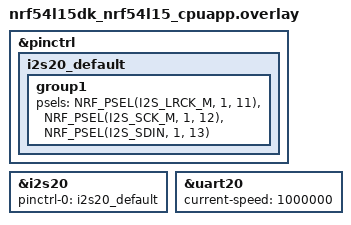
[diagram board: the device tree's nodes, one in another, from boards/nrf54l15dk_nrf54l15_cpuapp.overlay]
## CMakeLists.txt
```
#
# Copyright (c) 2024 Nordic Semiconductor
#
# SPDX-License-Identifier: LicenseRef-Nordic-5-Clause
#

cmake_minimum_required(VERSION 3.20.0)
find_package(Zephyr REQUIRED HINTS $ENV{ZEPHYR_BASE})
project(conn_time_sync)

target_include_directories(app PRIVATE include)
target_sources(app PRIVATE src/main.c src/timed_led_toggle.c src/timed_i2s.c src/buttons_leds.c)

if (CONFIG_BT_CENTRAL)
    target_sources(app PRIVATE src/central.c)
endif()

if (CONFIG_BT_PERIPHERAL)
    target_sources(app PRIVATE src/peripheral.c)
endif()

if (CONFIG_SOC_SERIES_NRF54LX)
    target_sources(app PRIVATE src/controller_time_nrf54.c)
else()
    MESSAGE(FATAL_ERROR "Unsupported series")
endif()
```

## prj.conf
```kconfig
#
# Copyright (c) 2024 Nordic Semiconductor
#
# SPDX-License-Identifier: LicenseRef-Nordic-5-Clause
#

CONFIG_NCS_SAMPLES_DEFAULTS=y

CONFIG_BT_DEVICE_NAME="Conn time sync"
CONFIG_BT=y
CONFIG_BT_PERIPHERAL=y
CONFIG_BT_CENTRAL=y
CONFIG_BT_MAX_CONN=3
CONFIG_BT_CTLR_SDC_PERIPHERAL_COUNT=1

CONFIG_BT_GATT_CLIENT=y

CONFIG_CONSOLE=y
CONFIG_CONSOLE_SUBSYS=y
CONFIG_CONSOLE_HANDLER=y
CONFIG_CONSOLE_GETCHAR=y

CONFIG_BT_CTLR_SDC_CONN_ANCHOR_POINT_REPORT=y
CONFIG_BT_HCI_VS_EVT_USER=y

CONFIG_NRFX_GPPI=y

CONFIG_I2S=y

CONFIG_FLASH=y
CONFIG_FLASH_MAP=y

CONFIG_SPI=y
CONFIG_SPI_NOR=y
CONFIG_SPI_NOR_FLASH_LAYOUT_PAGE_SIZE=4096
CONFIG_NORDIC_QSPI_NOR=n 
```

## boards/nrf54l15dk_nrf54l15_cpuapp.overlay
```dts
&pinctrl {
	i2s20_default: i2s20_default {
		group1 {
			psels = <NRF_PSEL(I2S_LRCK_M, 1, 11)>,
				<NRF_PSEL(I2S_SCK_M, 1, 12)>,
				<NRF_PSEL(I2S_SDIN, 1, 13)>;
		};
	};
};

&i2s20 {
	status = "okay";
	pinctrl-0 = <&i2s20_default>;
	pinctrl-names = "default";
};

&uart20 {
	current-speed = <1000000>;
};
```

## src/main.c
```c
/*
 * Copyright (c) 2024 Nordic Semiconductor ASA
 *
 * SPDX-License-Identifier: LicenseRef-Nordic-5-Clause
 */

#include "conn_time_sync.h"

int main(void)
{
	choose_device_role();
}
```

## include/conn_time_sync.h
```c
/*
 * Copyright (c) 2024 Nordic Semiconductor ASA
 *
 * SPDX-License-Identifier: LicenseRef-Nordic-5-Clause
 */

#ifndef CONN_TIME_SYNC_H__
#define CONN_TIME_SYNC_H__

/**
 * @file
 * @defgroup conn_time_sync Definitions for the connection time sync application.
 * @{
 * @brief Definitions for the connection time sync application.
 *
 * This file contains common definitions and API declarations
 * used by the application.
 */

#include <stdint.h>
#include <stdbool.h>
#include <zephyr/kernel.h>

/** @brief  Timed action service UUID */
#define BT_UUID_TIMED_ACTION_SERVICE_VAL \
	BT_UUID_128_ENCODE(0xA88278D0, 0x7009, 0x4BEE, 0xA6F8, 0xE1DC3FF02B92)
#define BT_UUID_TIMED_ACTION_SERVICE \
	BT_UUID_DECLARE_128(BT_UUID_TIMED_ACTION_SERVICE_VAL)

/** @brief Timed action characteristic UUID */
#define BT_UUID_TIMED_ACTION_CHAR_VAL \
	BT_UUID_128_ENCODE(0xA88278D1, 0x7009, 0x4BEE, 0xA6F8, 0xE1DC3FF02B92)
#define BT_UUID_TIMED_ACTION_CHAR \
	BT_UUID_DECLARE_128(BT_UUID_TIMED_ACTION_CHAR_VAL)

/** @brief Start central demo. */
void central_start(void);

/** @brief Start peripheral demo. */
void peripheral_start(void);

/** @brief The timed action message
 *
 * The timed action message represents the information
 * sent from the central to the peripheral to allow time synchronization.
 * The anchor point information is the common time reference between
 * the central and peripheral.
 *
 * This samples transmits the anchor point time and trigger time
 * in a single packet. Other applications may consider sending those
 * separately.
 */
struct timed_action {
	uint64_t anchor_point_us_central_clock;
	uint16_t anchor_point_event_counter;
	uint64_t trigger_time_us_central_clock;
	bool led_value;
} __packed;

static inline void timed_action_print(struct timed_action *action)
{
	printk("c_anchor point (time=%llu, counter=%u), c_trigger_time %llu, value %d\n",
		action->anchor_point_us_central_clock,
		action->anchor_point_event_counter,
		action->trigger_time_us_central_clock,
		action->led_value);
}

/** @brief Obtain the current Bluetooth controller time.
 *
 * The timestamps are based upon this clock.
 *
 * @return The current controller time.
 */
uint64_t controller_time_us_get(void);

/** @brief Set the controller to trigger a PPI event at the given timestamp.
 *
 * @param timestamp_us The timestamp where it will trigger.
 */
void controller_time_trigger_set(uint64_t timestamp_us);

/** @brief Get the address of the event that will trigger.
 *
 * @return The address of the event that will trigger.
 */
uint32_t controller_time_trigger_event_addr_get(void);

/** @brief Initialize the module handling timed toggling of an LED.
 *
 * @return 0 on success, failure otherwise.
 */
int timed_led_toggle_init(void);

/** @brief Toggle the LED using the given value at the given timestamp.
 *
 * @param value The LED value.
 * @param timestamp_us The time when the LED will be set, in microseconds.
 *                     The time is specified in controller clock units.
 */
void timed_led_toggle_trigger_at(uint8_t value, uint32_t timestamp_us);

/** @brief Initialize the flash for storing timed I2S data by erasing.
 *
 * @return 0 on success, failure otherwise.
 */
int timed_i2s_flash_init(void);

/** @brief Dump flash over UART in chunks.
 * 
 */
void timed_i2s_flash_dump(void);

/** @brief Initialize the module handling timed I2S and set up a PPI channel to capture the local clock.
 *
 * @return 0 on success, failure otherwise.
 */
int timed_i2s_init(void);

/** @brief Read I2S values and write the timestamped data to flash.
 *
 * @return 0 on success, failure otherwise.
 */
int timed_i2s_read(void);

/** @brief Stop the I2S stream and clear the queue.
 *
 * @return 0 on success, failure otherwise.
 */
int timed_i2s_drop(void);

/** @brief Update the time difference between the central and local clock.
 *
 * @param time_diff_us The new time difference.
 */
void timed_i2s_set_time_diff(uint64_t time_diff_us);

/** @brief Choose the device role with buttons.
 *
 * @return 0 on success, failure otherwise.
 */
int choose_device_role(void);

/** @brief Turn the given LED on.
 *
 * @param led The LED number.
 */
void led_on(int led);

/** @brief Wait for a button press while debouncing the input.
 * 
 */
void wait_for_button_press(void);

#endif

/**
 * @}
 */
```

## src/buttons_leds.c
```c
#include <zephyr/drivers/gpio.h>
#include "conn_time_sync.h"

#define SW1_NODE DT_ALIAS(sw1)
#define SW2_NODE DT_ALIAS(sw2)
#define SW3_NODE DT_ALIAS(sw3)

#define LED0_NODE DT_ALIAS(led0)
#define LED2_NODE DT_ALIAS(led2)
#define LED3_NODE DT_ALIAS(led3)

static const struct gpio_dt_spec button1 = GPIO_DT_SPEC_GET(SW1_NODE, gpios);
static const struct gpio_dt_spec button2 = GPIO_DT_SPEC_GET(SW2_NODE, gpios);
static const struct gpio_dt_spec button3 = GPIO_DT_SPEC_GET(SW3_NODE, gpios);

static const struct gpio_dt_spec led0 = GPIO_DT_SPEC_GET(LED0_NODE, gpios);
static const struct gpio_dt_spec led2 = GPIO_DT_SPEC_GET(LED2_NODE, gpios);
static const struct gpio_dt_spec led3 = GPIO_DT_SPEC_GET(LED3_NODE, gpios);

int choose_device_role(void)
{
    if (!device_is_ready(button1.port) || !device_is_ready(button2.port) || !device_is_ready(button3.port)) {
        printk("Button devices are not ready\n");
        return -1;
    }

    if (!device_is_ready(led0.port) || !device_is_ready(led2.port) || !device_is_ready(led3.port)) {
        printk("LED devices are not ready\n");
        return -1;
    }

	gpio_pin_configure_dt(&button1, GPIO_INPUT);
    gpio_pin_configure_dt(&button2, GPIO_INPUT);
    gpio_pin_configure_dt(&button3, GPIO_INPUT);

    gpio_pin_configure_dt(&led0, GPIO_OUTPUT_INACTIVE);
    gpio_pin_configure_dt(&led2, GPIO_OUTPUT_INACTIVE);
    gpio_pin_configure_dt(&led3, GPIO_OUTPUT_INACTIVE);

    printk("Press Button 1 to dump flash data, Button 2 for CENTRAL role, or Button 3 for PERIPHERAL role.\n");

	while (1) {
        if (gpio_pin_get_dt(&button1) == 1) {
        	k_msleep(250);
            timed_i2s_flash_dump();
            led_on(3);
            break;
        }

        if (gpio_pin_get_dt(&button2) == 1) {
        	k_msleep(250);
            printk("Central. Starting scanning\n");
            central_start();
            break;
        }

        if (gpio_pin_get_dt(&button3) == 1) {
        	k_msleep(250);
            printk("Peripheral. Starting advertising\n");
            peripheral_start();
            break;
        }

        k_msleep(50);
    }

    return 0;
}

void led_on(int led)
{
    if (led == 0) {
        gpio_pin_set_dt(&led0, 1);
    } else if (led == 2) {
        gpio_pin_set_dt(&led2, 1);
    } else if (led == 3) {
        gpio_pin_set_dt(&led3, 1);
    }
}

void wait_for_button_press(void)
{
    while (1) {
        if (gpio_pin_get_dt(&button1) == 1) {
        	k_msleep(250);
            break;
        }
        k_msleep(50);
    }
}
```

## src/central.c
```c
/*
 * Copyright (c) 2024 Nordic Semiconductor ASA
 *
 * SPDX-License-Identifier: LicenseRef-Nordic-5-Clause
 */

#include <zephyr/sys/atomic.h>
#include <zephyr/bluetooth/bluetooth.h>
#include <zephyr/bluetooth/conn.h>
#include <zephyr/bluetooth/hci.h>
#include <bluetooth/services/nus.h>
#include "conn_time_sync.h"
#include <bluetooth/hci_vs_sdc.h>

#define LED_TOGGLE_TIME_OFFSET_US 50000

#define ADV_NAME_STR_MAX_LEN (sizeof(CONFIG_BT_DEVICE_NAME))

static void scan_start(void);

static bool led_value;
static uint8_t volatile conn_count;

static const struct bt_uuid *timed_char_uuid = BT_UUID_TIMED_ACTION_CHAR;

static struct {
	atomic_t last_anchor_point_in_use;
	uint16_t timed_action_char_handle;
	uint16_t last_anchor_point_event_counter;
	uint64_t last_anchor_point_timestamp;
	struct timed_action timed_action_msg;
	struct bt_gatt_discover_params discovery_params;
} conn_state[CONFIG_BT_MAX_CONN];

static void send_timestamp_to_peripheral(struct bt_conn *conn, void *data)
{
	int err;
	struct bt_conn_info conn_info;
	uint64_t toggle_time_us = *(uint64_t *)data;

	err = bt_conn_get_info(conn, &conn_info);
	if (err) {
		return;
	}

	uint8_t conn_index = bt_conn_index(conn);

	if (conn_info.state != BT_CONN_STATE_CONNECTED) {
		return;
	}

	if (conn_state[conn_index].timed_action_char_handle == 0) {
		/* Service discovery not yet complete. */
		return;
	}

	if (atomic_test_and_set_bit(&conn_state[conn_index].last_anchor_point_in_use, 0)) {
		return;
	}

	conn_state[conn_index].timed_action_msg.anchor_point_us_central_clock =
		conn_state[conn_index].last_anchor_point_timestamp;
	conn_state[conn_index].timed_action_msg.anchor_point_event_counter =
		conn_state[conn_index].last_anchor_point_event_counter;
	conn_state[conn_index].timed_action_msg.trigger_time_us_central_clock = toggle_time_us;
	conn_state[conn_index].timed_action_msg.led_value = led_value;

	atomic_clear_bit(&conn_state[conn_index].last_anchor_point_in_use, 0);

	err = bt_gatt_write_without_response(conn,
		conn_state[conn_index].timed_action_char_handle,
		&conn_state[conn_index].timed_action_msg,
		sizeof(struct timed_action),
		false);
	if (err) {
		printk("Failed writing to characteristic\n");
	} else {
		// printk("Sent to conn index %d: ", conn_index);
		// timed_action_print(&conn_state[conn_index].timed_action_msg);
	}
}

static void sync_led_toggle()
{
	uint64_t local_time_us = controller_time_us_get();
	uint64_t toggle_time_us = local_time_us + LED_TOGGLE_TIME_OFFSET_US;

	led_value = !led_value;

	timed_led_toggle_trigger_at(led_value, toggle_time_us);

	bt_conn_foreach(BT_CONN_TYPE_LE, send_timestamp_to_peripheral, &toggle_time_us);
}

static bool adv_data_parse_cb(struct bt_data *data, void *user_data)
{
	char *name = user_data;
	uint8_t len;

	switch (data->type) {
	case BT_DATA_NAME_SHORTENED:
	case BT_DATA_NAME_COMPLETE:
		len = MIN(data->data_len, ADV_NAME_STR_MAX_LEN - 1);
		memcpy(name, data->data, len);
		name[len] = '\0';
		return false;
	default:
		return true;
	}
}

static void device_found(const bt_addr_le_t *addr, int8_t rssi, uint8_t type,
			 struct net_buf_simple *ad)
{
	char name_str[ADV_NAME_STR_MAX_LEN] = {0};
	char addr_str[BT_ADDR_LE_STR_LEN];
	int err;

	/* We're only interested in connectable events */
	if (type != BT_GAP_ADV_TYPE_ADV_IND &&
	    type != BT_GAP_ADV_TYPE_ADV_DIRECT_IND) {
		return;
	}

	bt_data_parse(ad, adv_data_parse_cb, name_str);

	if (strncmp(name_str, CONFIG_BT_DEVICE_NAME, ADV_NAME_STR_MAX_LEN) != 0) {
		return;
	}

	bt_addr_le_to_str(addr, addr_str, sizeof(addr_str));
	printk("Device found: %s (RSSI %d)\n", addr_str, rssi);

	if (bt_le_scan_stop()) {
		return;
	}

	struct bt_conn *unused_conn = NULL;

	err = bt_conn_le_create(addr, BT_CONN_LE_CREATE_CONN,
				BT_LE_CONN_PARAM(8, 8, 0, 200), &unused_conn);
	if (err) {
		printk("Create conn to %s failed (%d)\n", addr_str, err);
		scan_start();
	}

	if (unused_conn) {
		bt_conn_unref(unused_conn);
	}
}

static void scan_start(void)
{
	int err;

	err = bt_le_scan_start(BT_LE_SCAN_ACTIVE_CONTINUOUS, device_found);
	if (err) {
		printk("Scanning failed to start (err %d)\n", err);
		return;
	}

	printk("Scanning started\n");
}

static uint8_t on_service_discover(struct bt_conn *conn,
	const struct bt_gatt_attr *attr,
	struct bt_gatt_discover_params *params)
{
	if (attr) {
		uint8_t conn_index = bt_conn_index(conn);

		conn_state[conn_index].timed_action_char_handle =
			bt_gatt_attr_value_handle(attr);
		printk("Service discovery completed\n");
	} else {
		printk("Service discovery failed\n");
	}

	return BT_GATT_ITER_STOP;
}

static void connected(struct bt_conn *conn, uint8_t err)
{
	char addr[BT_ADDR_LE_STR_LEN];

	bt_addr_le_to_str(bt_conn_get_dst(conn), addr, sizeof(addr));

	if (err) {
		printk("Failed to connect to %s 0x%02x %s\n", addr, err, bt_hci_err_to_str(err));

		scan_start();
		return;
	}

	printk("Connected: %s\n", addr);

	uint8_t conn_index = bt_conn_index(conn);

	conn_state[conn_index].discovery_params.uuid = timed_char_uuid;
	conn_state[conn_index].discovery_params.func = on_service_discover;
	conn_state[conn_index].discovery_params.start_handle = BT_ATT_FIRST_ATTRIBUTE_HANDLE;
	conn_state[conn_index].discovery_params.end_handle = BT_ATT_LAST_ATTRIBUTE_HANDLE;
	conn_state[conn_index].discovery_params.type = BT_GATT_DISCOVER_CHARACTERISTIC;

	err = bt_gatt_discover(conn, &conn_state[conn_index].discovery_params);
	if (err) {
		printk("Discovery failed, %d\n", err);
	}

	const uint8_t peripheral_conn_count = 1;

	conn_count++;
	if (conn_count < CONFIG_BT_MAX_CONN - peripheral_conn_count) {
		scan_start();
	}
}

static void disconnected(struct bt_conn *conn, uint8_t reason)
{
	char addr[BT_ADDR_LE_STR_LEN];

	bt_addr_le_to_str(bt_conn_get_dst(conn), addr, sizeof(addr));

	printk("Disconnected: %s, reason 0x%02x %s\n", addr, reason, bt_hci_err_to_str(reason));

	conn_count--;

	uint8_t conn_index = bt_conn_index(conn);

	/* Reset state */
	memset(&conn_state[conn_index], 0, sizeof(conn_state));

	const uint8_t peripheral_conn_count = 1;

	if (conn_count == CONFIG_BT_MAX_CONN - peripheral_conn_count - 1) {
		scan_start();
	}
}

static bool on_conn_param_req(struct bt_conn *conn, struct bt_le_conn_param *param)
{
	ARG_UNUSED(conn);
	ARG_UNUSED(param);

	return false;
}

static struct bt_conn_cb conn_callbacks = {
	.connected = connected,
	.disconnected = disconnected,
	.le_param_req = on_conn_param_req,
};

static bool on_vs_evt(struct net_buf_simple *buf)
{
	uint8_t *subevent_code;
	struct bt_conn *conn;
	sdc_hci_subevent_vs_conn_anchor_point_update_report_t *evt = NULL;

	subevent_code = net_buf_simple_pull_mem(
		buf,
		sizeof(*subevent_code));

	switch (*subevent_code) {
	case SDC_HCI_SUBEVENT_VS_CONN_ANCHOR_POINT_UPDATE_REPORT:
		evt = (void *)buf->data;
		break;
	default:
		return false;
	}

	if (!evt) {
		return false;
	}

	conn = bt_hci_conn_lookup_handle(evt->conn_handle);
	if (!conn) {
		return true;
	}

	uint8_t conn_index = bt_conn_index(conn);

	bt_conn_unref(conn);
	conn = NULL;

	if (atomic_test_and_set_bit(&conn_state[conn_index].last_anchor_point_in_use, 0)) {
		return true;
	}

	conn_state[conn_index].last_anchor_point_timestamp = evt->anchor_point_us;
	conn_state[conn_index].last_anchor_point_event_counter = evt->event_counter;

	atomic_clear_bit(&conn_state[conn_index].last_anchor_point_in_use, 0);

	return true;
}

void central_start(void)
{
	int err;

	err = bt_enable(NULL);
	if (err) {
		printk("Bluetooth init failed (err %d)\n", err);
		return;
	}

	err = bt_hci_register_vnd_evt_cb(on_vs_evt);
	if (err) {
		printk("Failed to register HCI VS callback\n");
		return;
	}

	sdc_hci_cmd_vs_conn_anchor_point_update_event_report_enable_t enable_params = {
		.enable = true
	};

	err = hci_vs_sdc_conn_anchor_point_update_event_report_enable(&enable_params);
	if (err) {
		printk("Failed to enable connection anchor point update events\n");
		return;
	}

	timed_led_toggle_init();

	bt_conn_cb_register(&conn_callbacks);

	scan_start();

	timed_i2s_flash_init();
	led_on(0);

	wait_for_button_press();
	timed_i2s_init();

	int ret = 0;
	while (ret != -1) {
		ret = timed_i2s_read();
		if (ret == 0) {
			sync_led_toggle();
		}
	}

	timed_i2s_drop();
	led_on(2);
}
```

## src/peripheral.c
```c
/*
 * Copyright (c) 2024 Nordic Semiconductor ASA
 *
 * SPDX-License-Identifier: LicenseRef-Nordic-5-Clause
 */

#include <zephyr/sys/atomic.h>
#include <zephyr/bluetooth/bluetooth.h>
#include <zephyr/bluetooth/conn.h>
#include <zephyr/bluetooth/hci.h>
#include <bluetooth/services/nus.h>
#include <bluetooth/services/nus_client.h>
#include <bluetooth/hci_vs_sdc.h>

#include "conn_time_sync.h"

static const struct bt_data ad[] = {
	BT_DATA_BYTES(BT_DATA_FLAGS, (BT_LE_AD_GENERAL | BT_LE_AD_NO_BREDR)),
	BT_DATA(BT_DATA_NAME_COMPLETE, CONFIG_BT_DEVICE_NAME, sizeof(CONFIG_BT_DEVICE_NAME) - 1),
};

static atomic_t last_timed_action_in_use;
static struct timed_action last_timed_action;

static uint32_t conn_interval_us_get(const struct bt_conn *conn)
{
	struct bt_conn_info info;

	if (bt_conn_get_info(conn, &info)) {
		return 0;
	}

	return BT_CONN_INTERVAL_TO_US(info.le.interval);
}

static ssize_t time_sync_data_received(struct bt_conn *conn,
					     const struct bt_gatt_attr *attr,
					     const void *buf, uint16_t len,
					     uint16_t offset, uint8_t flags)
{
	__ASSERT_NO_MSG(len == sizeof(struct timed_action));
	__ASSERT_NO_MSG(offset == 0);

	struct timed_action *params = (void *)buf;

	__ASSERT_NO_MSG(params->trigger_time_us_central_clock >
			params->anchor_point_us_central_clock);

	if (!atomic_test_and_set_bit(&last_timed_action_in_use, 0)) {
		memcpy(&last_timed_action, params, sizeof(*params));
		atomic_clear_bit(&last_timed_action_in_use, 0);
	}

	// printk("Received: ");

	// timed_action_print(params);

	return len;
}

BT_GATT_SERVICE_DEFINE(timed_toggle_service,
	BT_GATT_PRIMARY_SERVICE(BT_UUID_TIMED_ACTION_SERVICE),
	BT_GATT_CHARACTERISTIC(BT_UUID_TIMED_ACTION_CHAR,
		BT_GATT_CHRC_WRITE_WITHOUT_RESP,
		BT_GATT_PERM_READ | BT_GATT_PERM_WRITE, NULL, time_sync_data_received, NULL));

static void adv_start(void)
{
	int err;

	err = bt_le_adv_start(BT_LE_ADV_CONN_FAST_2, ad, ARRAY_SIZE(ad), NULL, 0);
	if (err) {
		printk("Advertising failed to start (err %d)\n", err);
		return;
	}

	printk("Advertising started\n");
}

static void connected(struct bt_conn *conn, uint8_t err)
{
	char addr[BT_ADDR_LE_STR_LEN];

	bt_addr_le_to_str(bt_conn_get_dst(conn), addr, sizeof(addr));

	if (err) {
		printk("Failed to connect to %s 0x%02x %s\n", addr, err, bt_hci_err_to_str(err));

		adv_start();
		return;
	}

	printk("Connected: %s\n", addr);
}

static void disconnected(struct bt_conn *conn, uint8_t reason)
{
	char addr[BT_ADDR_LE_STR_LEN];

	bt_addr_le_to_str(bt_conn_get_dst(conn), addr, sizeof(addr));

	printk("Disconnected: %s, reason 0x%02x %s\n", addr, reason, bt_hci_err_to_str(reason));

	adv_start();
}

static struct bt_conn_cb conn_callbacks = {
	.connected = connected,
	.disconnected = disconnected,
};

static uint64_t central_timestamp_to_local_clock(uint64_t central_timestamp_us,
						 uint16_t conn_interval_us,
						 uint64_t central_anchor_us,
						 uint64_t peripheral_anchor_us,
						 uint16_t central_event_count,
						 uint16_t peripheral_event_count)
{
	int32_t event_counter_diff = central_event_count - peripheral_event_count;
	int32_t anchor_point_time_diff_us = event_counter_diff * conn_interval_us;
	uint64_t peripheral_time_us_at_central_anchor =
		peripheral_anchor_us + anchor_point_time_diff_us;
	int64_t anchor_to_timestamp = central_timestamp_us - central_anchor_us;

	return peripheral_time_us_at_central_anchor + anchor_to_timestamp;
}

static bool on_vs_evt(struct net_buf_simple *buf)
{
	uint8_t *subevent_code;
	struct bt_conn *conn;
	sdc_hci_subevent_vs_conn_anchor_point_update_report_t *evt = NULL;

	subevent_code = net_buf_simple_pull_mem(
		buf,
		sizeof(*subevent_code));

	switch (*subevent_code) {
	case SDC_HCI_SUBEVENT_VS_CONN_ANCHOR_POINT_UPDATE_REPORT:
		evt = (void *)buf->data;
		break;
	default:
		return false;
	}

	if (!evt) {
		return false;
	}

	conn = bt_hci_conn_lookup_handle(evt->conn_handle);
	if (!conn) {
		return true;
	}

	uint16_t conn_interval_us = conn_interval_us_get(conn);

	bt_conn_unref(conn);
	conn = NULL;

	if (atomic_test_and_set_bit(&last_timed_action_in_use, 0)) {
		return true;
	}

	uint64_t controller_time_us = controller_time_us_get();

	uint64_t trigger_time_local = central_timestamp_to_local_clock(
		last_timed_action.trigger_time_us_central_clock,
		conn_interval_us,
		last_timed_action.anchor_point_us_central_clock,
		evt->anchor_point_us,
		last_timed_action.anchor_point_event_counter,
		evt->event_counter);

	if (controller_time_us + 500 < trigger_time_local) {
		timed_led_toggle_trigger_at(last_timed_action.led_value, trigger_time_local);
	}

	uint64_t time_difference = last_timed_action.trigger_time_us_central_clock - trigger_time_local;

	atomic_clear_bit(&last_timed_action_in_use, 0);

	timed_i2s_set_time_diff(time_difference);

	return true;
}

void peripheral_start(void)
{
	int err;

	err = bt_enable(NULL);
	if (err) {
		printk("Bluetooth init failed (err %d)\n", err);
		return;
	}

	err = bt_hci_register_vnd_evt_cb(on_vs_evt);
	if (err) {
		printk("Failed to register HCI VS callback\n");
		return;
	}

	sdc_hci_cmd_vs_conn_anchor_point_update_event_report_enable_t enable_params = {
		.enable = true
	};

	err = hci_vs_sdc_conn_anchor_point_update_event_report_enable(&enable_params);
	if (err) {
		printk("Failed to enable connection anchor point update events\n");
		return;
	}

	timed_led_toggle_init();

	bt_conn_cb_register(&conn_callbacks);

	adv_start();

	timed_i2s_flash_init();
	led_on(0);

	wait_for_button_press();
	timed_i2s_init();

	while (timed_i2s_read() != -1);

	timed_i2s_drop();
	led_on(2);
}
```

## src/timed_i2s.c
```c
#include <zephyr/kernel.h>
#include <zephyr/drivers/i2s.h>
#include <nrfx_i2s.h>
#include <hal/nrf_i2s.h>
#include <nrfx_grtc.h>
#include <helpers/nrfx_gppi.h>
#include <zephyr/drivers/flash.h>
#include "conn_time_sync.h"

#define SAMPLE_FREQUENCY    8000
#define SAMPLE_BIT_WIDTH    32
#define NUMBER_OF_CHANNELS  1
#define BLOCK_SIZE          4080 
#define TIMEOUT             0

#define FLASH_SECTOR_SIZE   4096
#define FLASH_MAX_SIZE      1024 * 1024
#define FLASH_READ_CHUNK    64 

static const struct device *i2s_dev = DEVICE_DT_GET(DT_NODELABEL(i2s20));
static const struct device *flash_dev = DEVICE_DT_GET(DT_NODELABEL(mx25r64));

K_MEM_SLAB_DEFINE_STATIC(i2s_mem_slab, BLOCK_SIZE, 8, 4);

static off_t flash_write_offset = 0;
static uint64_t time_diff = 0;

struct __packed ts_block {
    uint64_t local_ts;
    uint64_t central_ts;
    int32_t samples[BLOCK_SIZE / 4];
};

static struct ts_block flash_write_data;

static int write_to_flash(uint64_t local_ts, uint64_t central_ts, int32_t *samples)
{
    if (flash_write_offset + FLASH_SECTOR_SIZE > FLASH_MAX_SIZE) {
        printk("Flash log area full.\n");
        return -1;
    }

    flash_write_data.local_ts = local_ts;
    flash_write_data.central_ts = central_ts;
    memcpy(flash_write_data.samples, samples, BLOCK_SIZE);

    int ret = flash_write(flash_dev, flash_write_offset, &flash_write_data, FLASH_SECTOR_SIZE);
    if (ret != 0) {
        printk("Flash write failed: %d\n", ret);
        return -1;
    }

    flash_write_offset += FLASH_SECTOR_SIZE;

    return 0;
}

int timed_i2s_flash_init(void)
{
    if (!device_is_ready(flash_dev)) {
		printk("Flash device is not ready\n");
		return -1;
	}

    printk("Erasing flash...\n");

    int ret = flash_erase(flash_dev, flash_write_offset, FLASH_MAX_SIZE);
    if (ret != 0) {
        printk("Flash erase failed: %d\n", ret);
        return -1;
    }

    printk("Erasing flash finished.\n");

    return 0;
}

void timed_i2s_flash_dump(void)
{
    if (!device_is_ready(flash_dev)) {
		printk("Flash device is not ready\n");
		return;
	}

    uint8_t buf[FLASH_READ_CHUNK];
    off_t addr = 0;

    printk("Dumping flash...\n");

    while (addr < FLASH_MAX_SIZE) {
        int ret = flash_read(flash_dev, addr, buf, FLASH_READ_CHUNK);
        if (ret != 0) {
            printk("Flash read failed: %d\n", ret);
            break;
        }

        for (int i = 0; i < FLASH_READ_CHUNK; i++) {
            printk("%02x", buf[i]);
        }

        addr += FLASH_READ_CHUNK;
    }

    printk("\nDumping flash finished.\n");
}

int timed_i2s_init(void)
{
	uint8_t ppi_chan_i2s;

    if (nrfx_gppi_channel_alloc(&ppi_chan_i2s) != NRFX_SUCCESS) {
		printk("Failed allocating PPI chan for I2S\n");
		return -ENOMEM;
	}

    nrfx_gppi_channel_endpoints_setup(ppi_chan_i2s,
        nrf_i2s_event_address_get(NRF_I2S20, NRF_I2S_EVENT_RXPTRUPD),
        nrf_grtc_task_address_get(NRF_GRTC, nrf_grtc_sys_counter_capture_task_get(0)));

	nrfx_gppi_channels_enable(BIT(ppi_chan_i2s));

    struct i2s_config i2s_cfg = {
        .word_size = SAMPLE_BIT_WIDTH,
        .channels = NUMBER_OF_CHANNELS,
        .format = I2S_FMT_DATA_FORMAT_I2S,
        .options = I2S_OPT_BIT_CLK_MASTER | I2S_OPT_FRAME_CLK_MASTER,
        .frame_clk_freq = SAMPLE_FREQUENCY,
        .mem_slab = &i2s_mem_slab,
        .block_size = BLOCK_SIZE,
        .timeout = TIMEOUT
    };

    int ret = i2s_configure(i2s_dev, I2S_DIR_RX, &i2s_cfg);
    if (ret != 0) {
		printk("i2s_configure failed with %d error\n", ret);
		return -1;
    }

    ret = i2s_trigger(i2s_dev, I2S_DIR_RX, I2S_TRIGGER_START);
	if (ret != 0) {
		printk("i2s_trigger failed with %d error\n", ret);
        return -1;
	}

    return 0;
}

int timed_i2s_read(void)
{
    void *mem_block;
    size_t size;

    int ret = i2s_read(i2s_dev, &mem_block, &size);
    if (ret != 0) {
        return ret;
    }

    uint64_t local_ts = nrf_grtc_sys_counter_cc_get(NRF_GRTC, 0);
    uint64_t central_ts = local_ts + time_diff;
    int32_t *samples = (int32_t *)mem_block;

    printk("local: %llu central: %llu\n", local_ts, central_ts);

    ret = write_to_flash(local_ts, central_ts, samples);

    k_mem_slab_free(&i2s_mem_slab, mem_block);

    return ret;
}

int timed_i2s_drop(void)
{
    int ret = i2s_trigger(i2s_dev, I2S_DIR_RX, I2S_TRIGGER_DROP);
	if (ret != 0) {
		printk("i2s_trigger failed with %d error\n", ret);
        return -1;
	}

    return 0;
}

void timed_i2s_set_time_diff(uint64_t time_diff_us)
{
    time_diff = time_diff_us;
}
```
